# ATmega329P register map
Vendor: Atmel; File version: 1.0
CPU: other r0p0, little endian, no MPU, no FPU, 4 interrupt priority bits
Registers are 8-bit, read-write, reset 0x0 unless marked. A register's access mark holds for its fields unless they carry their own. Offsets are from the block's base; [hi:lo] are bit positions; {n}, {i} and the like mark numbered series.

## BOOT_LOAD — Bootloader
Base 0x00000057
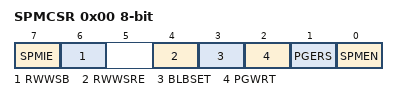
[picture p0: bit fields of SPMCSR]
0x00 SPMCSR — Store Program Memory Control Register
  [7] SPMIE — SPM Interrupt Enable
  [6] RWWSB — Read While Write Section Busy
  [4] RWWSRE — Read While Write section read enable
  [3] BLBSET — Boot Lock Bit Set
  [2] PGWRT — Page Write
  [1] PGERS — Page Erase
  [0] SPMEN — Store Program Memory Enable

## CPU — CPU Registers
Base 0x0000003E
0x00 GPIOR0 — General Purpose IO Register 0
0x0C GPIOR1 — General Purpose IO Register 1
0x0D GPIOR2 — General Purpose IO Register 2
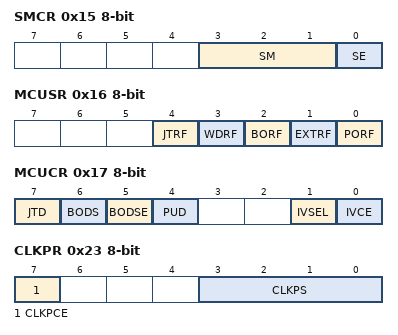
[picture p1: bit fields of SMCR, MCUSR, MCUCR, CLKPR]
0x15 SMCR — Sleep Mode Control Register
  [3:1] SM — Sleep Mode Select bits
    0=IDLE; 1=ADC (ADC Noise Reduction (If Available)); 2=PDOWN (Power Down); 3=PSAVE (Power Save); 6=STDBY (Standby)
  [0] SE — Sleep Enable
0x16 MCUSR — MCU Status Register
  [4] JTRF — JTAG Reset Flag
  [3] WDRF — Watchdog Reset Flag
  [2] BORF — Brown-out Reset Flag
  [1] EXTRF — External Reset Flag
  [0] PORF — Power-on reset flag
0x17 MCUCR — MCU Control Register
  [7] JTD — JTAG Interface Disable
  [6] BODS — BOD Sleep
  [5] BODSE — BOD Sleep Enable
  [4] PUD — Pull-up disable
  [1] IVSEL — Interrupt Vector Select
  [0] IVCE — Interrupt Vector Change Enable
0x23 CLKPR — Clock Prescale Register
  [7] CLKPCE — Clock Prescaler Change Enable
  [3:0] CLKPS — Clock Prescaler Select Bits
    0=1; 1=2; 2=4; 3=8; 4=16; 5=32; 6=64; 7=128; 8=256
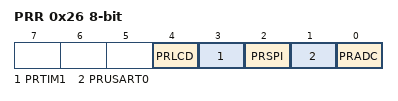
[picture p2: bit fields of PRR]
0x26 PRR — Power Reduction Register
  [4] PRLCD — Power Reduction LCD
  [3] PRTIM1 — Power Reduction Timer/Counter1
  [2] PRSPI — Power Reduction Serial Peripheral Interface
  [1] PRUSART0 — Power Reduction USART
  [0] PRADC — Power Reduction ADC
0x28 OSCCAL — Oscillator Calibration Value
  [7:0] OSCCAL — Oscillator Calibration

## EEPROM
Base 0x0000003F
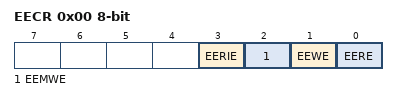
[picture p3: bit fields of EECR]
0x00 EECR — EEPROM Control Register
  [3] EERIE — EEPROM Ready Interrupt Enable
  [2] EEMWE — EEPROM Master Write Enable
  [1] EEWE — EEPROM Write Enable
  [0] EERE — EEPROM Read Enable
0x01 EEDR — EEPROM Data Register
0x02 EEAR 16-bit (reset mask 0xFF) — EEPROM Read/Write Access Bytes

## EXINT — External Interrupts
Base 0x0000003C
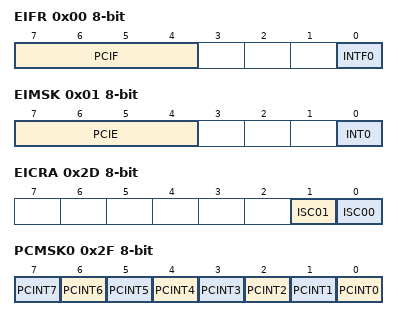
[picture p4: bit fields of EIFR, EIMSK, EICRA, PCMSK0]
0x00 EIFR — External Interrupt Flag Register
  [7:4] PCIF — Pin Change Interrupt Flags
  [0] INTF0 — External Interrupt Flag 0
0x01 EIMSK — External Interrupt Mask Register
  [7:4] PCIE — Pin Change Interrupt Enables
  [0] INT0 — External Interrupt Request 0 Enable
0x2D EICRA — External Interrupt Control Register A
  [1] ISC01 — External Interrupt Sense Control 0 Bit 1
  [0] ISC00 — External Interrupt Sense Control 0 Bit 0
    0=Low Level of INTX; 1=Any Logical Change of INTX
0x2F PCMSK0 — Pin Change Mask Register 0
  [n] PCINT{n} (n=0..7) — Pin Change Mask Register pin {n}
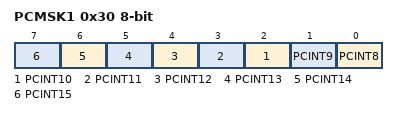
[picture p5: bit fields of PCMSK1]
0x30 PCMSK1 — Pin Change Mask Register 1
  [n-8] PCINT{n} (n=8..15) — Pin Change Mask Register pin {n}

## JTAG — JTAG Interface
Base 0x00000051
0x00 OCDR — On-Chip Debug Related Register in I/O Memory
0x03 MCUSR — MCU Status Register
  [4] JTRF — JTAG Reset Flag
0x04 MCUCR — MCU Control Register
  [7] JTD — JTAG Interface Disable

## LCD — Liquid Crystal Display
Base 0x000000E4
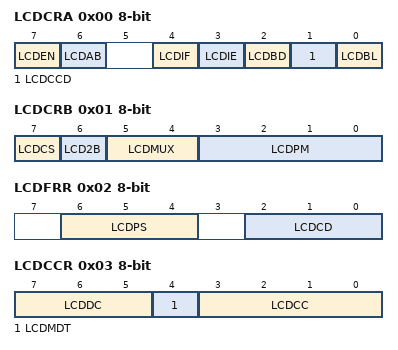
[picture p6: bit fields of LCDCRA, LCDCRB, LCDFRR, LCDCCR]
0x00 LCDCRA — LCD Control Register A
  [7] LCDEN — LCD Enable
  [6] LCDAB — LCD A or B waveform
  [4] LCDIF — LCD Interrupt Flag
  [3] LCDIE — LCD Interrupt Enable
  [2] LCDBD — LCD Buffer Disable
  [1] LCDCCD — LCD Contrast Control Disable
  [0] LCDBL — LCD Blanking
0x01 LCDCRB — LCD Control and Status Register B
  [7] LCDCS — LCD CLock Select
  [6] LCD2B — LCD 1/2 Bias Select
  [5:4] LCDMUX — LCD Mux Selects
  [3:0] LCDPM — LCD Port Masks
    0=SEG0:12; 1=SEG0:14; 2=SEG0:15; 3=SEG0:18; 4=SEG0:20; 5=SEG0:22; 6=SEG0:23; 7=SEG0:24; 8=SEG0:26; 9=SEG0:28; 10=SEG0:30; 11=SEG0:32; 12=SEG0:34; 13=SEG0:36; 14=SEG0:38; 15=SEG0:39
0x02 LCDFRR — LCD Frame Rate Register
  [6:4] LCDPS — LCD Prescaler Selects
    0=ClkLCD/16; 1=ClkLCD/64; 2=ClkLCD/128; 3=ClkLCD/256; 4=ClkLCD/512; 5=ClkLCD/1024; 6=ClkLCD/2048; 7=ClkLCD/4096
  [2:0] LCDCD — LCD Clock Dividers
    {v}={v+1} (v=0..7)
0x03 LCDCCR — LCD Contrast Control Register
  [7:5] LCDDC
    0=300us; 1=70us; 2=150us; 3=450us; 4=575us; 5=850us; 6=1150us; 7=50% of LCD clock
  [4] LCDMDT — LCD Maximum Drive Time
  [3:0] LCDCC — LCD Contrast Controls
    0=2.60V; 1=2.65V; 2=2.70V; 3=2.75V; 4=2.80V; 5=2.85V; 6=2.90V; 7=2.95V; 8=3.00V; 9=3.05V; 10=3.10V; 11=3.15V; 12=3.20V; 13=3.25V; 14=3.30V; 15=3.35V
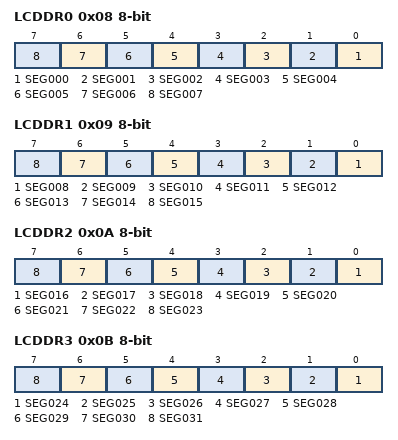
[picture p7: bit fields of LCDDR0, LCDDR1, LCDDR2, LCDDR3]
0x08 LCDDR0 — LCD Data Register 0
  [n] SEG{n:03} (n=0..7) — LCD memory bit segment
0x09 LCDDR1 — LCD Data Register 1
  [n-8] SEG{n:03} (n=8..15) — LCD memory bit segment
0x0A LCDDR2 — LCD Data Register 2
  [n-16] SEG{n:03} (n=16..23) — LCD memory bit segment
0x0B LCDDR3 — LCD Data Register 3
  [n-24] SEG{n:03} (n=24..31) — LCD memory bit segment
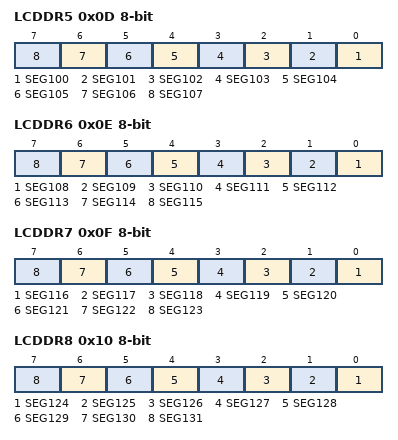
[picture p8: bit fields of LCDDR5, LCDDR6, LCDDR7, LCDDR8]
0x0D LCDDR5 — LCD Data Register 5
  [n-100] SEG{n} (n=100..107) — LCD memory bit segment
0x0E LCDDR6 — LCD Data Register 6
  [n-108] SEG{n} (n=108..115) — LCD memory bit segment
0x0F LCDDR7 — LCD Data Register 7
  [n-116] SEG{n} (n=116..123) — LCD memory bit segment
0x10 LCDDR8 — LCD Data Register 8
  [n-124] SEG{n} (n=124..131) — LCD memory bit segment
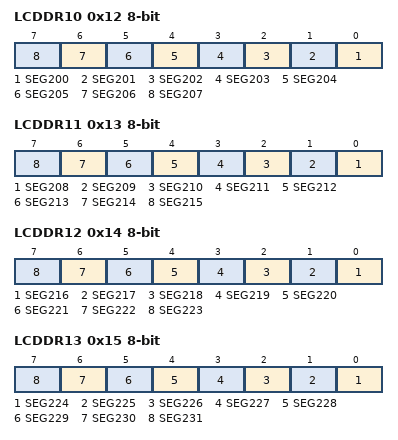
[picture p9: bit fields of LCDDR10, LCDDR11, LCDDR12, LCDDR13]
0x12 LCDDR10 — LCD Data Register 10
  [n-200] SEG{n} (n=200..207) — LCD memory bit segment
0x13 LCDDR11 — LCD Data Register 11
  [n-208] SEG{n} (n=208..215) — LCD memory bit segment
0x14 LCDDR12 — LCD Data Register 12
  [n-216] SEG{n} (n=216..223) — LCD memory bit segment
0x15 LCDDR13 — LCD Data Register 13
  [n-224] SEG{n} (n=224..231) — LCD memory bit segment
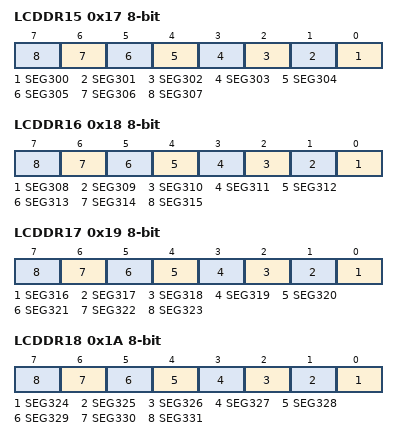
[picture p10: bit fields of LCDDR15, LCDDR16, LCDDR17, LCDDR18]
0x17 LCDDR15 — LCD Data Register 15
  [n-300] SEG{n} (n=300..307) — LCD memory bit segment
0x18 LCDDR16 — LCD Data Register 16
  [n-308] SEG{n} (n=308..315) — LCD memory bit segment
0x19 LCDDR17 — LCD Data Register 17
  [n-316] SEG{n} (n=316..323) — LCD memory bit segment
0x1A LCDDR18 — LCD Data Register 18
  [n-324] SEG{n} (n=324..331) — LCD memory bit segment
